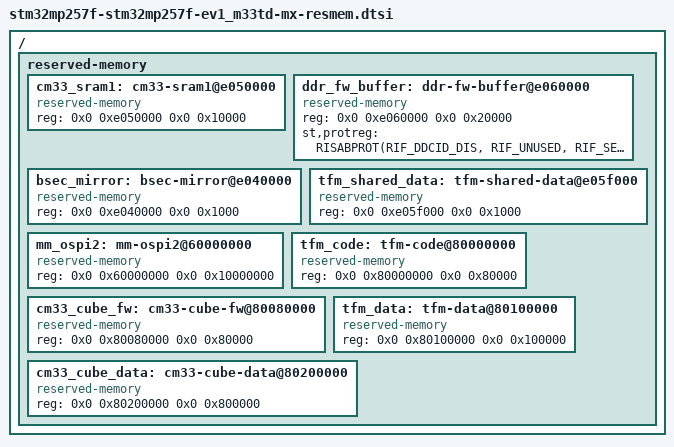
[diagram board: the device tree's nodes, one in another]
// SPDX-License-Identifier: (GPL-2.0-or-later OR BSD-3-Clause)
/*
 * Copyright (C) 2025, STMicroelectronics - All Rights Reserved
 * Author: STM32CubeMX code generation for STMicroelectronics.
 */

/* For more information on Device Tree configuration, please refer to
 * https://wiki.st.com/stm32mpu/wiki/Category:Device_tree_configuration
 */
/{

	reserved-memory{
		#address-cells = <2>;
		#size-cells = <2>;
		ranges;

		/* USER CODE BEGIN reserved-memory */
		cm33_sram1: cm33-sram1@e050000 {
			compatible = "reserved-memory";
			reg = <0x0 0xe050000 0x0 0x10000>;
			#memory-region-cells = <0>;
		};

		ddr_fw_buffer: ddr-fw-buffer@e060000 {
			compatible = "reserved-memory";
			reg = <0x0 0xe060000 0x0 0x20000>;
			#memory-region-cells = <0>;
			st,protreg = <RISABPROT(RIF_DDCID_DIS, RIF_UNUSED, RIF_SEC, RIF_PRIV, RIF_CFEN, RIF_CID2_BF, RIF_CID2_BF, RIF_UNUSED)>;
		};

		bsec_mirror:bsec-mirror@e040000{
			compatible = "reserved-memory";
			reg = <0x0 0xe040000 0x0 0x1000>;
			#memory-region-cells = <0>;
		};

		tfm_shared_data:tfm-shared-data@e05f000{
			compatible = "reserved-memory";
			reg = <0x0 0xe05f000 0x0 0x1000>;
			#memory-region-cells = <0>;
		};

		mm_ospi2:mm-ospi2@60000000{
			compatible = "reserved-memory";
			reg = <0x0 0x60000000 0x0 0x10000000>;
			#memory-region-cells = <0>;
		};

		tfm_code:tfm-code@80000000{
			compatible = "reserved-memory";
			reg = <0x0 0x80000000 0x0 0x80000>;
			#memory-region-cells = <0>;
		};

		cm33_cube_fw:cm33-cube-fw@80080000{
			compatible = "reserved-memory";
			reg = <0x0 0x80080000 0x0 0x80000>;
			#memory-region-cells = <0>;
		};

		tfm_data:tfm-data@80100000{
			compatible = "reserved-memory";
			reg = <0x0 0x80100000 0x0 0x100000>;
			#memory-region-cells = <0>;
		};

		cm33_cube_data:cm33-cube-data@80200000{
			compatible = "reserved-memory";
			reg = <0x0 0x80200000 0x0 0x800000>;
			#memory-region-cells = <0>;
		};
		/* USER CODE END reserved-memory */
	};
};

/* USER CODE BEGIN addons */
/* USER CODE END addons */
